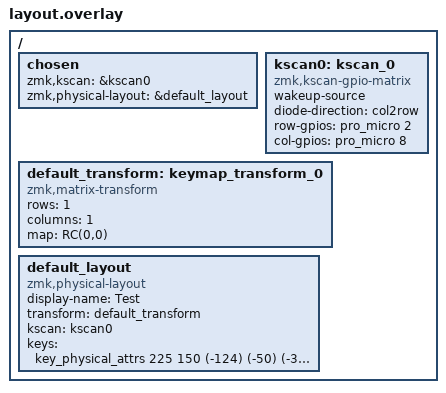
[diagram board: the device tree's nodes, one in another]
#include <dt-bindings/zmk/matrix_transform.h>
#include <physical_layouts.dtsi>

/ {
    chosen {
        zmk,kscan = &kscan0;
        zmk,physical-layout = &default_layout;
    };

    kscan0: kscan_0 {
        compatible = "zmk,kscan-gpio-matrix";
        wakeup-source;
        diode-direction = "col2row";
        row-gpios = <&pro_micro 2 (GPIO_ACTIVE_HIGH | GPIO_PULL_DOWN)>;
        col-gpios = <&pro_micro 8 GPIO_ACTIVE_HIGH>;
    };

    default_transform: keymap_transform_0 {
        compatible = "zmk,matrix-transform";
        rows = <1>;
        columns = <1>;
        map = <
            RC(0,0)
        >;
    };

    default_layout: default_layout {
        compatible = "zmk,physical-layout";
        display-name = "Test";
        transform = <&default_transform>;
        kscan = <&kscan0>;
        keys = <&key_physical_attrs 225 150 (-124) (-50) (-3000) 100 200>;
    };
};
